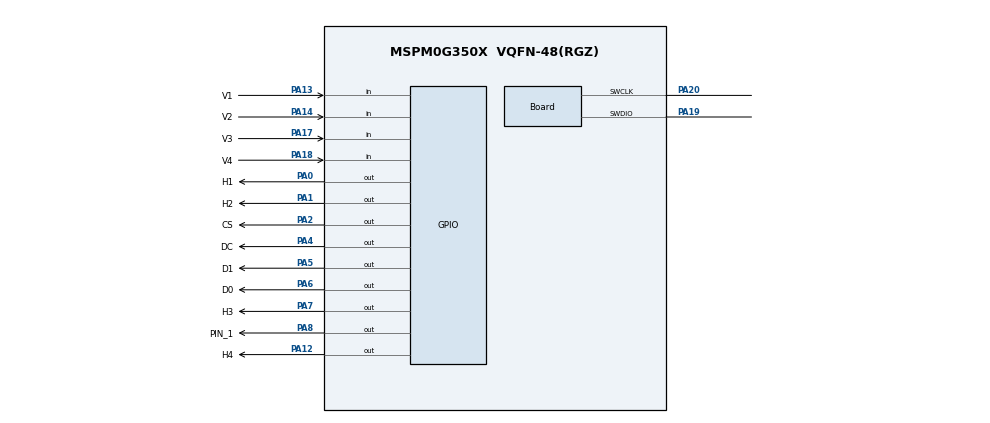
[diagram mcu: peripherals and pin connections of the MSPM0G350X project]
/**
 * @cliArgs --device "MSPM0G350X" --package "VQFN-48(RGZ)" --part "Default" --product "mspm0_sdk@1.20.01.06"
 * @versions {"tool":"1.18.1+3343"}
 */

/**
 * Import the modules used in this configuration.
 */
const Board         = scripting.addModule("/ti/driverlib/Board");
const GPIO          = scripting.addModule("/ti/driverlib/GPIO", {}, false);
const GPIO1         = GPIO.addInstance();
const GPIO2         = GPIO.addInstance();
const GPIO3         = GPIO.addInstance();
const SYSCTL        = scripting.addModule("/ti/driverlib/SYSCTL");
const UART          = scripting.addModule("/ti/driverlib/UART", {}, false);
const UART1         = UART.addInstance();
const ProjectConfig = scripting.addModule("/ti/project_config/ProjectConfig");

/**
 * Write custom configuration values to the imported modules.
 */
const gate7  = system.clockTree["MFCLKGATE"];
gate7.enable = true;

const gate8  = system.clockTree["MFPCLKGATE"];
gate8.enable = true;

Board.peripheral.$assign          = "DEBUGSS";
Board.peripheral.swclkPin.$assign = "PA20";
Board.peripheral.swdioPin.$assign = "PA19";

GPIO1.$name                         = "GPIO_GRP_0";
GPIO1.associatedPins.create(4);
GPIO1.associatedPins[0].$name       = "CS";
GPIO1.associatedPins[0].assignedPin = "2";
GPIO1.associatedPins[0].pin.$assign = "PA2";
GPIO1.associatedPins[1].$name       = "DC";
GPIO1.associatedPins[1].assignedPin = "4";
GPIO1.associatedPins[1].pin.$assign = "PA4";
GPIO1.associatedPins[2].$name       = "D0";
GPIO1.associatedPins[2].assignedPin = "6";
GPIO1.associatedPins[2].pin.$assign = "PA6";
GPIO1.associatedPins[3].$name       = "D1";
GPIO1.associatedPins[3].assignedPin = "5";
GPIO1.associatedPins[3].pin.$assign = "PA5";

GPIO2.$name                              = "KEY";
GPIO2.associatedPins.create(8);
GPIO2.associatedPins[0].$name            = "H1";
GPIO2.associatedPins[0].assignedPin      = "0";
GPIO2.associatedPins[0].internalResistor = "PULL_UP";
GPIO2.associatedPins[0].pin.$assign      = "PA0";
GPIO2.associatedPins[1].$name            = "H2";
GPIO2.associatedPins[1].assignedPin      = "1";
GPIO2.associatedPins[1].internalResistor = "PULL_UP";
GPIO2.associatedPins[1].pin.$assign      = "PA1";
GPIO2.associatedPins[2].$name            = "H3";
GPIO2.associatedPins[2].assignedPin      = "7";
GPIO2.associatedPins[2].pin.$assign      = "PA7";
GPIO2.associatedPins[3].$name            = "H4";
GPIO2.associatedPins[3].assignedPin      = "12";
GPIO2.associatedPins[3].pin.$assign      = "PA12";
GPIO2.associatedPins[4].$name            = "V1";
GPIO2.associatedPins[4].direction        = "INPUT";
GPIO2.associatedPins[4].assignedPin      = "13";
GPIO2.associatedPins[4].internalResistor = "PULL_DOWN";
GPIO2.associatedPins[4].pin.$assign      = "PA13";
GPIO2.associatedPins[5].$name            = "V2";
GPIO2.associatedPins[5].assignedPin      = "14";
GPIO2.associatedPins[5].direction        = "INPUT";
GPIO2.associatedPins[5].internalResistor = "PULL_DOWN";
GPIO2.associatedPins[5].pin.$assign      = "PA14";
GPIO2.associatedPins[6].$name            = "V3";
GPIO2.associatedPins[6].direction        = "INPUT";
GPIO2.associatedPins[6].internalResistor = "PULL_DOWN";
GPIO2.associatedPins[6].assignedPin      = "17";
GPIO2.associatedPins[6].pin.$assign      = "PA17";
GPIO2.associatedPins[7].$name            = "V4";
GPIO2.associatedPins[7].assignedPin      = "18";
GPIO2.associatedPins[7].direction        = "INPUT";
GPIO2.associatedPins[7].internalResistor = "PULL_DOWN";
GPIO2.associatedPins[7].pin.$assign      = "PA18";

GPIO3.$name                          = "LED";
GPIO3.associatedPins[0].$name        = "PIN_1";
GPIO3.associatedPins[0].assignedPin  = "8";
GPIO3.associatedPins[0].initialValue = "SET";
GPIO3.associatedPins[0].pin.$assign  = "PA8";

SYSCTL.MFCLKEn     = true;
SYSCTL.MFPCLKEn    = true;
SYSCTL.clockTreeEn = true;

UART1.$name                        = "UART_0";
UART1.targetBaudRate               = 115200;
UART1.enableFIFO                   = true;
UART1.rxFifoThreshold              = "DL_UART_RX_FIFO_LEVEL_ONE_ENTRY";
UART1.enableDMARX                  = false;
UART1.enableDMATX                  = false;
UART1.enabledInterrupts            = ["RX","TX"];
UART1.peripheral.$assign           = "UART0";
UART1.txPinConfig.$name            = "ti_driverlib_gpio_GPIOPinGeneric0";
UART1.rxPinConfig.$name            = "ti_driverlib_gpio_GPIOPinGeneric1";
UART1.rxPinConfig.enableConfig     = true;
UART1.rxPinConfig.internalResistor = "PULL_UP";

ProjectConfig.deviceSpin = "MSPM0G3507";

/**
 * Pinmux solution for unlocked pins/peripherals. This ensures that minor changes to the automatic solver in a future
 * version of the tool will not impact the pinmux you originally saw.  These lines can be completely deleted in order to
 * re-solve from scratch.
 */
UART1.peripheral.rxPin.$suggestSolution = "PA11";
UART1.peripheral.txPin.$suggestSolution = "PA10";
